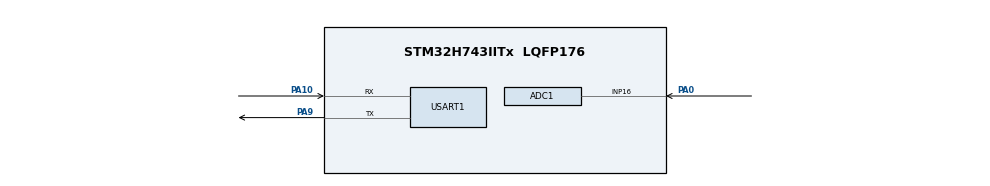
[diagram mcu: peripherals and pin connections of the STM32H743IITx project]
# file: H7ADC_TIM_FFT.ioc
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ADC1.Channel-0\#ChannelRegularConversion=ADC_CHANNEL_16
ADC1.ConversionDataManagement=ADC_CONVERSIONDATA_DMA_ONESHOT
ADC1.ExternalTrigConv=ADC_EXTERNALTRIG_T3_TRGO
ADC1.NbrOfConversionFlag=1
ADC1.OffsetNumber-0\#ChannelRegularConversion=ADC_OFFSET_NONE
ADC1.OffsetSignedSaturation-0\#ChannelRegularConversion=DISABLE
ADC1.Rank-0\#ChannelRegularConversion=1
ADC1.SamplingTime-0\#ChannelRegularConversion=ADC_SAMPLETIME_1CYCLE_5
ADC1.master=1
Dma.ADC1.0.Direction=DMA_PERIPH_TO_MEMORY
Dma.ADC1.0.EventEnable=DISABLE
Dma.ADC1.0.FIFOMode=DMA_FIFOMODE_DISABLE
Dma.ADC1.0.Instance=DMA1_Stream0
Dma.ADC1.0.MemDataAlignment=DMA_MDATAALIGN_HALFWORD
Dma.ADC1.0.MemInc=DMA_MINC_ENABLE
Dma.ADC1.0.Mode=DMA_NORMAL
Dma.ADC1.0.PeriphDataAlignment=DMA_PDATAALIGN_HALFWORD
Dma.ADC1.0.PeriphInc=DMA_PINC_DISABLE
Dma.ADC1.0.Polarity=HAL_DMAMUX_REQ_GEN_RISING
Dma.ADC1.0.Priority=DMA_PRIORITY_LOW
Dma.ADC1.0.RequestNumber=1
Dma.ADC1.0.SignalID=NONE
Dma.ADC1.0.SyncEnable=DISABLE
Dma.ADC1.0.SyncPolarity=HAL_DMAMUX_SYNC_NO_EVENT
Dma.ADC1.0.SyncRequestNumber=1
Dma.ADC1.0.SyncSignalID=NONE
Dma.Request0=ADC1
Mcu.Family=STM32H7
Mcu.Name=STM32H743IITx
Mcu.Package=LQFP176
NVIC.DMA1_Stream0_IRQn=true\:0\:0\:false\:false\:true\:false\:true
NVIC.PriorityGroup=NVIC_PRIORITYGROUP_4
PA0.Mode=IN16-Single-Ended
PA0.Signal=ADC1_INP16
PA10.Mode=Asynchronous
PA10.Signal=USART1_RX
PA13\ (JTMS/SWDIO).Mode=Serial_Wire
PA13\ (JTMS/SWDIO).Signal=DEBUG_JTMS-SWDIO
PA14\ (JTCK/SWCLK).Mode=Serial_Wire
PA14\ (JTCK/SWCLK).Signal=DEBUG_JTCK-SWCLK
PA9.Mode=Asynchronous
PA9.Signal=USART1_TX
PC14-OSC32_IN\ (OSC32_IN).Mode=LSE-External-Oscillator
PC14-OSC32_IN\ (OSC32_IN).Signal=RCC_OSC32_IN
PC15-OSC32_OUT\ (OSC32_OUT).Mode=LSE-External-Oscillator
PC15-OSC32_OUT\ (OSC32_OUT).Signal=RCC_OSC32_OUT
PH0-OSC_IN\ (PH0).Mode=HSE-External-Oscillator
PH0-OSC_IN\ (PH0).Signal=RCC_OSC_IN
PH1-OSC_OUT\ (PH1).Mode=HSE-External-Oscillator
PH1-OSC_OUT\ (PH1).Signal=RCC_OSC_OUT
ProjectManager.HeapSize=0x200
ProjectManager.StackSize=0x400
ProjectManager.TargetToolchain=MDK-ARM V5
RCC.ADCFreq_Value=75000000
RCC.APB1Freq_Value=120000000
RCC.APB2Freq_Value=120000000
RCC.APB3Freq_Value=120000000
RCC.APB4Freq_Value=120000000
RCC.CortexFreq_Value=480000000
RCC.D1PPRE=RCC_APB3_DIV2
RCC.D2PPRE1=RCC_APB1_DIV2
RCC.D2PPRE2=RCC_APB2_DIV2
RCC.D3PPRE=RCC_APB4_DIV2
RCC.DIVM1=5
RCC.DIVM2=2
RCC.DIVN1=192
RCC.DIVN2=12
RCC.HCLKFreq_Value=240000000
RCC.HPRE=RCC_HCLK_DIV2
RCC.HSE_VALUE=25000000
RCC.PLL2FRACN=0
RCC.PLLFRACN=0
RCC.PLLSourceVirtual=RCC_PLLSOURCE_HSE
RCC.PWR_Regulator_Voltage_Scale=PWR_REGULATOR_VOLTAGE_SCALE0
RCC.SYSCLKFreq_VALUE=480000000
RCC.SYSCLKSource=RCC_SYSCLKSOURCE_PLLCLK
RCC.USBFreq_Value=480000000
TIM3.Period=200-1
TIM3.Prescaler=12-1
TIM3.TIM_MasterOutputTrigger=TIM_TRGO_UPDATE
USART1.VirtualMode-Asynchronous=VM_ASYNC
VP_TIM3_VS_ClockSourceINT.Mode=Internal
board=custom

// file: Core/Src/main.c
/* USER CODE BEGIN Header */
/**
  ******************************************************************************
  * @file           : main.c
  * @brief          : Main program body
  ******************************************************************************
  * @attention
  *
  * <h2><center>&copy; Copyright (c) 2026 STMicroelectronics.
  * All rights reserved.</center></h2>
  *
  * This software component is licensed by ST under Ultimate Liberty license
  * SLA0044, the "License"; You may not use this file except in compliance with
  * the License. You may obtain a copy of the License at:
  *                             www.st.com/SLA0044
  *
  ******************************************************************************
  */
/* USER CODE END Header */
#include "main.h"
#include "adc.h"
#include "dma.h"
#include "tim.h"
#include "usart.h"
#include "gpio.h"

/* USER CODE BEGIN Includes */
#include "fft.h"
#include "math.h"
#include "HMI.h"
/* USER CODE END Includes */

/* USER CODE BEGIN PV */
#define ADC_SIZE 		1024
#define DAC_SIZE 		1024

uint16_t ADC_Buffer[ADC_SIZE]={0};
uint8_t ADC_Flag=0;
float ADC_float[ADC_SIZE]={0};
/* USER CODE END PV */

void SystemClock_Config(void);

int main(void)
{

  /* MCU Configuration--------------------------------------------------------*/

  /* Reset of all peripherals, Initializes the Flash interface and the Systick. */
  HAL_Init();

  /* Configure the system clock */
  SystemClock_Config();

  /* Initialize all configured peripherals */
  MX_GPIO_Init();
  MX_DMA_Init();
  MX_ADC1_Init();
  MX_TIM3_Init();
  MX_USART1_UART_Init();
  /* USER CODE BEGIN 2 */
  HAL_ADCEx_Calibration_Start(&hadc1,ADC_CALIB_OFFSET,ADC_SINGLE_ENDED);
  HAL_TIM_Base_Start(&htim3);
  HAL_ADC_Start_DMA(&hadc1,(uint32_t*)ADC_Buffer,ADC_SIZE);
  /* USER CODE END 2 */

  /* Infinite loop */
  /* USER CODE BEGIN WHILE */
  while (1)
  {
		if(ADC_Flag==1){
		  ADC_Flag=0;
		  for (uint16_t i=0;i<ADC_SIZE;i++){
			  ADC_float[i]=(float)ADC_Buffer[i]/65536.0f*3.3f;
				//HMI_Wave("s0.id", 0, ADC_float[i]*100);
			  printf("%.3f\n",ADC_float[i]);
		  }
			FFT_Process();
			HAL_ADC_Start_DMA(&hadc1,(uint32_t*)ADC_Buffer,ADC_SIZE);
		}

    /* USER CODE END WHILE */

  }
}

void SystemClock_Config(void)
{
  RCC_OscInitTypeDef RCC_OscInitStruct = {0};
  RCC_ClkInitTypeDef RCC_ClkInitStruct = {0};

  /** Supply configuration update enable
  */
  HAL_PWREx_ConfigSupply(PWR_LDO_SUPPLY);
  /** Configure the main internal regulator output voltage
  */
  __HAL_PWR_VOLTAGESCALING_CONFIG(PWR_REGULATOR_VOLTAGE_SCALE0);

  while(!__HAL_PWR_GET_FLAG(PWR_FLAG_VOSRDY)) {}
  /** Macro to configure the PLL clock source
  */
  __HAL_RCC_PLL_PLLSOURCE_CONFIG(RCC_PLLSOURCE_HSE);
  /** Initializes the RCC Oscillators according to the specified parameters
  * in the RCC_OscInitTypeDef structure.
  */
  RCC_OscInitStruct.OscillatorType = RCC_OSCILLATORTYPE_HSE;
  RCC_OscInitStruct.HSEState = RCC_HSE_ON;
  RCC_OscInitStruct.PLL.PLLState = RCC_PLL_ON;
  RCC_OscInitStruct.PLL.PLLSource = RCC_PLLSOURCE_HSE;
  RCC_OscInitStruct.PLL.PLLM = 5;
  RCC_OscInitStruct.PLL.PLLN = 192;
  RCC_OscInitStruct.PLL.PLLP = 2;
  RCC_OscInitStruct.PLL.PLLQ = 2;
  RCC_OscInitStruct.PLL.PLLR = 2;
  RCC_OscInitStruct.PLL.PLLRGE = RCC_PLL1VCIRANGE_2;
  RCC_OscInitStruct.PLL.PLLVCOSEL = RCC_PLL1VCOWIDE;
  RCC_OscInitStruct.PLL.PLLFRACN = 0;
  if (HAL_RCC_OscConfig(&RCC_OscInitStruct) != HAL_OK)
  {
    Error_Handler();
  }
  /** Initializes the CPU, AHB and APB buses clocks
  */
  RCC_ClkInitStruct.ClockType = RCC_CLOCKTYPE_HCLK|RCC_CLOCKTYPE_SYSCLK
                              |RCC_CLOCKTYPE_PCLK1|RCC_CLOCKTYPE_PCLK2
                              |RCC_CLOCKTYPE_D3PCLK1|RCC_CLOCKTYPE_D1PCLK1;
  RCC_ClkInitStruct.SYSCLKSource = RCC_SYSCLKSOURCE_PLLCLK;
  RCC_ClkInitStruct.SYSCLKDivider = RCC_SYSCLK_DIV1;
  RCC_ClkInitStruct.AHBCLKDivider = RCC_HCLK_DIV2;
  RCC_ClkInitStruct.APB3CLKDivider = RCC_APB3_DIV2;
  RCC_ClkInitStruct.APB1CLKDivider = RCC_APB1_DIV2;
  RCC_ClkInitStruct.APB2CLKDivider = RCC_APB2_DIV2;
  RCC_ClkInitStruct.APB4CLKDivider = RCC_APB4_DIV2;

  if (HAL_RCC_ClockConfig(&RCC_ClkInitStruct, FLASH_LATENCY_4) != HAL_OK)
  {
    Error_Handler();
  }
}

/* USER CODE BEGIN 4 */
void HAL_ADC_ConvCpltCallback (ADC_HandleTypeDef *hadc){
	if(hadc==&hadc1){
		HAL_ADC_Stop(hadc);
		ADC_Flag=1;
	}
}
/* USER CODE END 4 */

void Error_Handler(void)
{
  __disable_irq();
  while (1)
  {
  }
}

/************************ (C) COPYRIGHT STMicroelectronics *****END OF FILE****/
